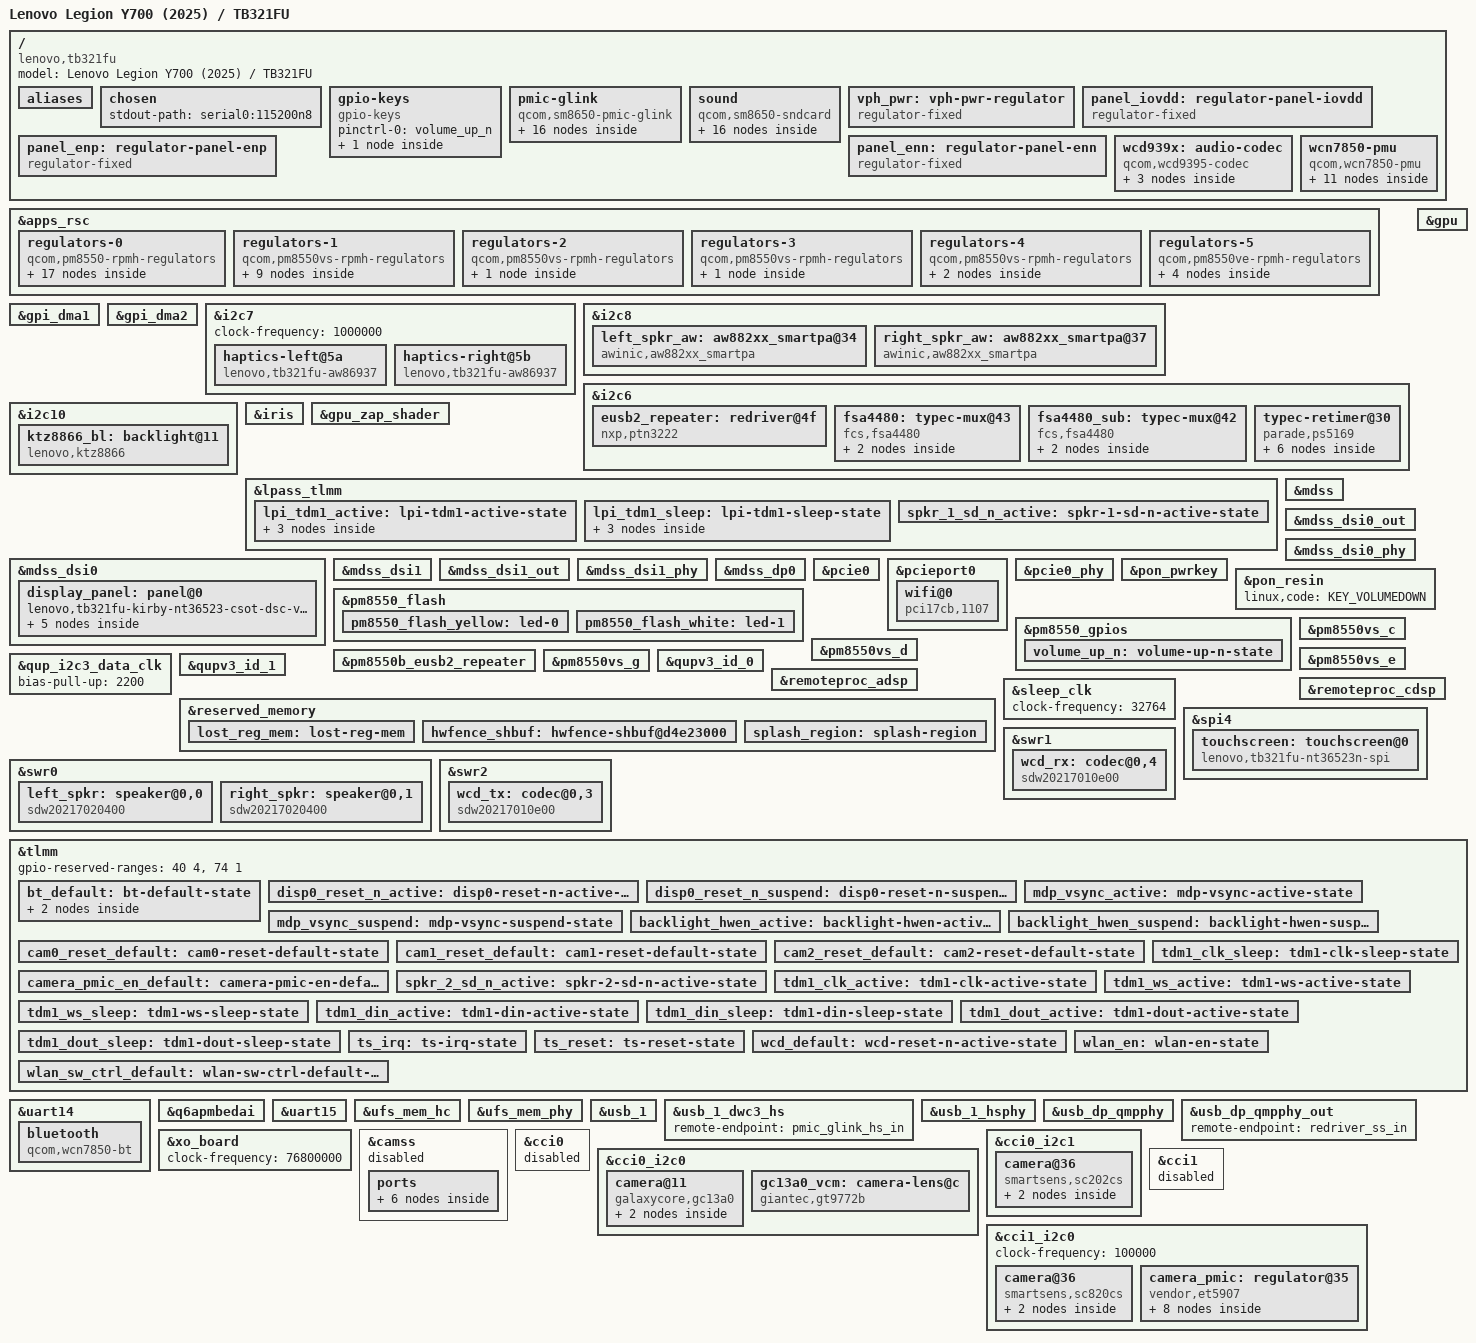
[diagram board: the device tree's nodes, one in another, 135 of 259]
// SPDX-License-Identifier: BSD-3-Clause
/*
 * Copyright (c) 2023, Linaro Limited
 */

/dts-v1/;

#include <dt-bindings/leds/common.h>
#include <dt-bindings/regulator/qcom,rpmh-regulator.h>
#include <dt-bindings/phy/phy.h>
#include "sm8650.dtsi"
#include "pm8550.dtsi"
#include "pm8550b.dtsi"
#define PMK8550VE_SID 8
#include "pm8550ve.dtsi"
#include "pm8550vs.dtsi"
#include "pmk8550.dtsi"

/delete-node/ &rmtfs_mem;
/delete-node/ &hwfence_shbuf;
/delete-node/ &remoteproc_mpss;
/delete-node/ &qlink_logging_mem;
/delete-node/ &mpss_dsm_mem;
/delete-node/ &mpss_dsm_mem_2;
/delete-node/ &mpss_mem;
/delete-node/ &q6_mpss_dtb_mem;

/ {
	model = "Lenovo Legion Y700 (2025) / TB321FU";
	compatible = "lenovo,tb321fu", "qcom,sm8650";

	aliases {
		serial0 = &uart15;
		serial1 = &uart14;
	};

	chosen {
		stdout-path = "serial0:115200n8";
	};

	gpio-keys {
		compatible = "gpio-keys";

		pinctrl-0 = <&volume_up_n>;
		pinctrl-names = "default";

		key-volume-up {
			label = "Volume Up";
			linux,code = <KEY_VOLUMEUP>;
			gpios = <&pm8550_gpios 6 GPIO_ACTIVE_LOW>;
			debounce-interval = <15>;
			linux,can-disable;
			wakeup-source;
		};
	};

		pmic-glink {
				compatible = "qcom,sm8650-pmic-glink",
					     "qcom,sm8550-pmic-glink",
					     "qcom,pmic-glink";
				#address-cells = <1>;
				#size-cells = <0>;
				c2-select-gpios = <&tlmm 58 GPIO_ACTIVE_HIGH>;
				secondary-audio-detect-gpios = <&tlmm 29 GPIO_ACTIVE_HIGH>;

				connector@0 {
					compatible = "usb-c-connector";
					reg = <0>;

			power-role = "dual";
			data-role = "dual";
			self-powered;

			ports {
				#address-cells = <1>;
				#size-cells = <0>;

				port@0 {
					reg = <0>;

					pmic_glink_hs_in: endpoint {
						remote-endpoint = <&usb_1_dwc3_hs>;
					};
				};

				port@1 {
					reg = <1>;

					pmic_glink_ss_in: endpoint {
						remote-endpoint = <&redriver_ss_out>;
					};
				};

				port@2 {
					reg = <2>;
					#address-cells = <1>;
					#size-cells = <0>;

					pmic_glink_sbu: endpoint@0 {
						reg = <0>;
						remote-endpoint = <&fsa4480_sbu_mux>;
					};

					pmic_glink_sbu_codec: endpoint@1 {
						reg = <1>;
						remote-endpoint = <&wcd_codec_headset_in>;
					};
					};
				};
			};

			connector@1 {
				compatible = "usb-c-connector";
				reg = <1>;

				power-role = "dual";
				data-role = "dual";
				self-powered;

				ports {
					#address-cells = <1>;
					#size-cells = <0>;

					port@1 {
						reg = <1>;

						pmic_glink_ss1_in: endpoint {
							remote-endpoint = <&redriver_ss1_out>;
						};
					};

					port@2 {
						reg = <2>;
						#address-cells = <1>;
						#size-cells = <0>;

						pmic_glink_sbu1: endpoint@0 {
							reg = <0>;
							remote-endpoint = <&fsa4480_sub_sbu_mux>;
						};

						pmic_glink_sbu1_codec: endpoint@1 {
							reg = <1>;
							remote-endpoint = <&wcd_codec_headset_in1>;
						};
					};
				};
			};
		};

	sound {
		compatible = "qcom,sm8650-sndcard", "qcom,sm8450-sndcard";
		model = "Lenovo-Y700-TB321FU";
		pinctrl-names = "default", "sleep";
			pinctrl-0 = <&tdm1_clk_active>, <&tdm1_ws_active>,
				    <&tdm1_din_active>, <&tdm1_dout_active>;
			pinctrl-1 = <&tdm1_clk_sleep>, <&tdm1_ws_sleep>,
				    <&tdm1_din_sleep>, <&tdm1_dout_sleep>;
		audio-routing = "IN1_HPHL", "HPHL_OUT",
				"IN2_HPHR", "HPHR_OUT",
				"AMIC1", "MIC BIAS1",
				"AMIC2", "MIC BIAS2",
				"AMIC3", "MIC BIAS3",
				"AMIC4", "MIC BIAS4",
				"AMIC5", "MIC BIAS4",
				"TX SWR_INPUT0", "ADC1_OUTPUT",
				"TX SWR_INPUT1", "ADC2_OUTPUT",
				"TX SWR_INPUT2", "ADC3_OUTPUT",
				"TX SWR_INPUT3", "ADC4_OUTPUT";

		wcd-playback-dai-link {
			link-name = "WCD Playback";

			cpu {
				sound-dai = <&q6apmbedai RX_CODEC_DMA_RX_0>;
			};

			codec {
				sound-dai = <&wcd939x 0>, <&swr1 0>, <&lpass_rxmacro 0>;
			};

			platform {
				sound-dai = <&q6apm>;
			};
		};

		wcd-capture-dai-link {
			link-name = "WCD Capture";

			cpu {
				sound-dai = <&q6apmbedai TX_CODEC_DMA_TX_3>;
			};

			codec {
				sound-dai = <&wcd939x 1>, <&swr2 1>, <&lpass_txmacro 0>;
			};

			platform {
				sound-dai = <&q6apm>;
			};
		};

		aw-spk-dai-link {
			link-name = "AW882xx Playback";

			cpu {
				sound-dai = <&q6apmbedai SECONDARY_TDM_RX_0>;
			};

			codec {
				sound-dai = <&left_spkr_aw>, <&right_spkr_aw>;
			};

			platform {
				sound-dai = <&q6apm>;
			};
		};

		/* Needs the DISPLAY_PORT_RX_0 path in the AudioReach topology. */
		dp-dai-link {
			link-name = "DisplayPort Playback";

			cpu {
				sound-dai = <&q6apmbedai DISPLAY_PORT_RX_0>;
			};

			codec {
				sound-dai = <&mdss_dp0>;
			};

			platform {
				sound-dai = <&q6apm>;
			};
		};
	};

	vph_pwr: vph-pwr-regulator {
		compatible = "regulator-fixed";

		regulator-name = "vph_pwr";
		regulator-min-microvolt = <3700000>;
		regulator-max-microvolt = <3700000>;

		regulator-always-on;
		regulator-boot-on;
	};


	panel_iovdd: regulator-panel-iovdd {
		compatible = "regulator-fixed";
		regulator-name = "panel_iovdd";
		regulator-min-microvolt = <1800000>;
		regulator-max-microvolt = <1800000>;
		gpio = <&pm8550ve_gpios 8 GPIO_ACTIVE_HIGH>;
		enable-active-high;
	};

	panel_enp: regulator-panel-enp {
		compatible = "regulator-fixed";
		regulator-name = "panel_enp";
		gpio = <&tlmm 72 GPIO_ACTIVE_HIGH>;
		enable-active-high;
	};

	panel_enn: regulator-panel-enn {
		compatible = "regulator-fixed";
		regulator-name = "panel_enn";
		gpio = <&tlmm 73 GPIO_ACTIVE_HIGH>;
		enable-active-high;
	};

	wcd939x: audio-codec {
		compatible = "qcom,wcd9395-codec", "qcom,wcd9390-codec";

		pinctrl-0 = <&wcd_default>;
		pinctrl-names = "default";

		qcom,micbias1-microvolt = <1800000>;
		qcom,micbias2-microvolt = <1800000>;
		qcom,micbias3-microvolt = <1800000>;
		qcom,micbias4-microvolt = <1800000>;
		qcom,mbhc-buttons-vthreshold-microvolt = <75000 150000 237000 500000 500000 500000 500000 500000>;
		qcom,mbhc-headset-vthreshold-microvolt = <1700000>;
		qcom,mbhc-headphone-vthreshold-microvolt = <50000>;
		qcom,rx-device = <&wcd_rx>;
		qcom,tx-device = <&wcd_tx>;

		reset-gpios = <&tlmm 107 GPIO_ACTIVE_LOW>;

	vdd-buck-supply = <&vreg_l15b_1p8>;
	vdd-rxtx-supply = <&vreg_l15b_1p8>;
	vdd-io-supply = <&vreg_l15b_1p8>;
	vdd-mic-bias-supply = <&vreg_bob1>;

		#sound-dai-cells = <1>;

		mode-switch;
		orientation-switch;

			port {
				#address-cells = <1>;
				#size-cells = <0>;

				wcd_codec_headset_in: endpoint@0 {
					reg = <0>;
					remote-endpoint = <&pmic_glink_sbu_codec>;
				};

				wcd_codec_headset_in1: endpoint@1 {
					reg = <1>;
					remote-endpoint = <&pmic_glink_sbu1_codec>;
				};
			};
	};

	wcn7850-pmu {
		compatible = "qcom,wcn7850-pmu";

		pinctrl-names = "default";
		pinctrl-0 = <&wlan_en>, <&bt_default>, <&wlan_sw_ctrl_default>;

		wlan-enable-gpios = <&tlmm 16 GPIO_ACTIVE_HIGH>;
		bt-enable-gpios = <&tlmm 17 GPIO_ACTIVE_HIGH>;

		vdd-supply = <&vreg_s4i_0p85>;
		vddio-supply = <&vreg_l15b_1p8>;
		vddio1p2-supply = <&vreg_l3c_1p2>;
		vddaon-supply = <&vreg_s2c_0p8>;
		vdddig-supply = <&vreg_s3c_0p9>;
		vddrfa1p2-supply = <&vreg_s1c_1p2>;
		vddrfa1p8-supply = <&vreg_s6c_1p8>;

		clocks = <&rpmhcc RPMH_RF_CLK1>;

		regulators {
			vreg_pmu_rfa_cmn: ldo0 {
				regulator-name = "vreg_pmu_rfa_cmn";
			};

			vreg_pmu_aon_0p59: ldo1 {
				regulator-name = "vreg_pmu_aon_0p59";
			};

			vreg_pmu_wlcx_0p8: ldo2 {
				regulator-name = "vreg_pmu_wlcx_0p8";
			};

			vreg_pmu_wlmx_0p85: ldo3 {
				regulator-name = "vreg_pmu_wlmx_0p85";
			};

			vreg_pmu_btcmx_0p85: ldo4 {
				regulator-name = "vreg_pmu_btcmx_0p85";
			};

			vreg_pmu_rfa_0p8: ldo5 {
				regulator-name = "vreg_pmu_rfa_0p8";
			};

			vreg_pmu_rfa_1p2: ldo6 {
				regulator-name = "vreg_pmu_rfa_1p2";
			};

			vreg_pmu_rfa_1p8: ldo7 {
				regulator-name = "vreg_pmu_rfa_1p8";
			};

			vreg_pmu_pcie_0p9: ldo8 {
				regulator-name = "vreg_pmu_pcie_0p9";
			};

			vreg_pmu_pcie_1p8: ldo9 {
				regulator-name = "vreg_pmu_pcie_1p8";
			};
		};
	};
};

&apps_rsc {
	regulators-0 {
		compatible = "qcom,pm8550-rpmh-regulators";

		vdd-bob1-supply = <&vph_pwr>;
		vdd-bob2-supply = <&vph_pwr>;
		vdd-l1-l4-l10-supply = <&vreg_s6c_1p8>;
		vdd-l2-l13-l14-supply = <&vreg_bob1>;
		vdd-l3-supply = <&vreg_s1c_1p2>;
		vdd-l5-l16-supply = <&vreg_bob1>;
		vdd-l6-l7-supply = <&vreg_bob1>;
		vdd-l8-l9-supply = <&vreg_bob1>;
		vdd-l11-supply = <&vreg_s1c_1p2>;
		vdd-l12-supply = <&vreg_s6c_1p8>;
		vdd-l15-supply = <&vreg_s6c_1p8>;
		vdd-l17-supply = <&vreg_bob2>;

		qcom,pmic-id = "b";

		vreg_bob1: bob1 {
			regulator-name = "vreg_bob1";
			regulator-min-microvolt = <3296000>;
			regulator-max-microvolt = <3960000>;
			regulator-initial-mode = <RPMH_REGULATOR_MODE_HPM>;
		};

		vreg_bob2: bob2 {
			regulator-name = "vreg_bob2";
			regulator-min-microvolt = <2720000>;
			regulator-max-microvolt = <3008000>;
			regulator-initial-mode = <RPMH_REGULATOR_MODE_HPM>;
		};

		vreg_l2b_3p0: ldo2 {
			regulator-name = "vreg_l2b_3p0";
			regulator-min-microvolt = <3008000>;
			regulator-max-microvolt = <3008000>;
			regulator-initial-mode = <RPMH_REGULATOR_MODE_HPM>;
			regulator-allow-set-load;
			regulator-allowed-modes = <RPMH_REGULATOR_MODE_LPM
						   RPMH_REGULATOR_MODE_HPM>;
		};

		vreg_l5b_3p1: ldo5 {
			regulator-name = "vreg_l5b_3p1";
			regulator-min-microvolt = <3104000>;
			regulator-max-microvolt = <3104000>;
			regulator-initial-mode = <RPMH_REGULATOR_MODE_HPM>;
			regulator-allow-set-load;
			regulator-allowed-modes = <RPMH_REGULATOR_MODE_LPM
						   RPMH_REGULATOR_MODE_HPM>;
		};

		vreg_l6b_1p8: ldo6 {
			regulator-name = "vreg_l6b_1p8";
			regulator-min-microvolt = <1800000>;
			regulator-max-microvolt = <3008000>;
			regulator-initial-mode = <RPMH_REGULATOR_MODE_HPM>;
			regulator-allow-set-load;
			regulator-allowed-modes = <RPMH_REGULATOR_MODE_LPM
						   RPMH_REGULATOR_MODE_HPM>;
		};

		vreg_l7b_1p8: ldo7 {
			regulator-name = "vreg_l7b_1p8";
			regulator-min-microvolt = <1800000>;
			regulator-max-microvolt = <3008000>;
			regulator-initial-mode = <RPMH_REGULATOR_MODE_HPM>;
		};

		vreg_l8b_1p8: ldo8 {
			regulator-name = "vreg_l8b_1p8";
			regulator-min-microvolt = <1800000>;
			regulator-max-microvolt = <3008000>;
			regulator-initial-mode = <RPMH_REGULATOR_MODE_HPM>;
			regulator-allow-set-load;
			regulator-allowed-modes = <RPMH_REGULATOR_MODE_LPM
						   RPMH_REGULATOR_MODE_HPM>;
		};

		vreg_l10b_1p8: ldo10 {
			regulator-name = "vreg_l10b_1p8";
			regulator-min-microvolt = <1800000>;
			regulator-max-microvolt = <1800000>;
			regulator-initial-mode = <RPMH_REGULATOR_MODE_HPM>;
			regulator-allow-set-load;
			regulator-boot-on;
			regulator-always-on;
			regulator-allowed-modes = <RPMH_REGULATOR_MODE_LPM
						   RPMH_REGULATOR_MODE_HPM>;
		};

		vreg_l11b_1p2: ldo11 {
			regulator-name = "vreg_l11b_1p2";
			regulator-min-microvolt = <1200000>;
			regulator-max-microvolt = <1504000>;
			regulator-initial-mode = <RPMH_REGULATOR_MODE_HPM>;
			regulator-allow-set-load;
			regulator-allowed-modes = <RPMH_REGULATOR_MODE_LPM
						   RPMH_REGULATOR_MODE_HPM>;
		};

		vreg_l12b_1p8: ldo12 {
			regulator-name = "vreg_l12b_1p8";
			regulator-min-microvolt = <1800000>;
			regulator-max-microvolt = <1800000>;
			regulator-initial-mode = <RPMH_REGULATOR_MODE_HPM>;
			regulator-allow-set-load;
			regulator-allowed-modes = <RPMH_REGULATOR_MODE_LPM
						   RPMH_REGULATOR_MODE_HPM>;
		};

		vreg_l13b_3p0: ldo13 {
			regulator-name = "vreg_l13b_3p0";
			regulator-min-microvolt = <3000000>;
			regulator-max-microvolt = <3000000>;
			regulator-initial-mode = <RPMH_REGULATOR_MODE_HPM>;
			regulator-allow-set-load;
			regulator-allowed-modes = <RPMH_REGULATOR_MODE_LPM
						   RPMH_REGULATOR_MODE_HPM>;
		};

		vreg_l14b_3p2: ldo14 {
			regulator-name = "vreg_l14b_3p2";
			regulator-min-microvolt = <3200000>;
			regulator-max-microvolt = <3200000>;
			regulator-initial-mode = <RPMH_REGULATOR_MODE_HPM>;
			regulator-allow-set-load;
			regulator-allowed-modes = <RPMH_REGULATOR_MODE_LPM
						   RPMH_REGULATOR_MODE_HPM>;
		};

		vreg_l15b_1p8: ldo15 {
			regulator-name = "vreg_l15b_1p8";
			regulator-min-microvolt = <1800000>;
			regulator-max-microvolt = <1800000>;
			regulator-initial-mode = <RPMH_REGULATOR_MODE_HPM>;
			regulator-allow-set-load;
			regulator-allowed-modes = <RPMH_REGULATOR_MODE_LPM
						   RPMH_REGULATOR_MODE_HPM>;
		};

		vreg_l16b_2p8: ldo16 {
			regulator-name = "vreg_l16b_2p8";
			regulator-min-microvolt = <2800000>;
			regulator-max-microvolt = <2800000>;
			regulator-initial-mode = <RPMH_REGULATOR_MODE_HPM>;
			regulator-allow-set-load;
			regulator-allowed-modes = <RPMH_REGULATOR_MODE_LPM
						   RPMH_REGULATOR_MODE_HPM>;
		};

		vreg_l17b_2p5: ldo17 {
			regulator-name = "vreg_l17b_2p5";
			regulator-min-microvolt = <2504000>;
			regulator-max-microvolt = <2504000>;
			regulator-initial-mode = <RPMH_REGULATOR_MODE_HPM>;
			regulator-allow-set-load;
			regulator-allowed-modes = <RPMH_REGULATOR_MODE_LPM
						   RPMH_REGULATOR_MODE_HPM>;
		};
	};

	regulators-1 {
		compatible = "qcom,pm8550vs-rpmh-regulators";

		vdd-l1-supply = <&vreg_s1c_1p2>;
		vdd-l2-supply = <&vreg_s1c_1p2>;
		vdd-l3-supply = <&vreg_s1c_1p2>;
		vdd-s1-supply = <&vph_pwr>;
		vdd-s2-supply = <&vph_pwr>;
		vdd-s3-supply = <&vph_pwr>;
		vdd-s4-supply = <&vph_pwr>;
		vdd-s5-supply = <&vph_pwr>;
		vdd-s6-supply = <&vph_pwr>;

		qcom,pmic-id = "c";

		vreg_s1c_1p2: smps1 {
			regulator-name = "vreg_s1c_1p2";
			regulator-min-microvolt = <1256000>;
			regulator-max-microvolt = <1348000>;
			regulator-initial-mode = <RPMH_REGULATOR_MODE_HPM>;
		};

		vreg_s2c_0p8: smps2 {
			regulator-name = "vreg_s2c_0p8";
			regulator-min-microvolt = <852000>;
			regulator-max-microvolt = <1036000>;
			regulator-initial-mode = <RPMH_REGULATOR_MODE_HPM>;
		};

		vreg_s3c_0p9: smps3 {
			regulator-name = "vreg_s3c_0p9";
			regulator-min-microvolt = <976000>;
			regulator-max-microvolt = <1064000>;
			regulator-initial-mode = <RPMH_REGULATOR_MODE_HPM>;
		};

		vreg_s4c_1p2: smps4 {
			regulator-name = "vreg_s4c_1p2";
			regulator-min-microvolt = <1224000>;
			regulator-max-microvolt = <1280000>;
			regulator-initial-mode = <RPMH_REGULATOR_MODE_HPM>;
		};

		vreg_s5c_0p7: smps5 {
			regulator-name = "vreg_s5c_0p7";
			regulator-min-microvolt = <752000>;
			regulator-max-microvolt = <900000>;
			regulator-initial-mode = <RPMH_REGULATOR_MODE_HPM>;
		};

		vreg_s6c_1p8: smps6 {
			regulator-name = "vreg_s6c_1p8";
			regulator-min-microvolt = <1856000>;
			regulator-max-microvolt = <2000000>;
			regulator-initial-mode = <RPMH_REGULATOR_MODE_HPM>;
		};

		vreg_l1c_1p2: ldo1 {
			regulator-name = "vreg_l1c_1p2";
			regulator-min-microvolt = <1200000>;
			regulator-max-microvolt = <1200000>;
			regulator-initial-mode = <RPMH_REGULATOR_MODE_HPM>;
			regulator-allow-set-load;
			regulator-allowed-modes = <RPMH_REGULATOR_MODE_LPM
						   RPMH_REGULATOR_MODE_HPM>;
		};

		vreg_l3c_1p2: ldo3 {
			regulator-name = "vreg_l3c_1p2";
			regulator-min-microvolt = <1200000>;
			regulator-max-microvolt = <1200000>;
			regulator-initial-mode = <RPMH_REGULATOR_MODE_HPM>;
			regulator-allow-set-load;
			regulator-allowed-modes = <RPMH_REGULATOR_MODE_LPM
						   RPMH_REGULATOR_MODE_HPM>;
		};
	};

	regulators-2 {
		compatible = "qcom,pm8550vs-rpmh-regulators";

		vdd-l1-supply = <&vreg_s3c_0p9>;

		qcom,pmic-id = "d";

		vreg_l1d_0p88: ldo1 {
			regulator-name = "vreg_l1d_0p88";
			regulator-min-microvolt = <912000>;
			regulator-max-microvolt = <920000>;
			regulator-initial-mode = <RPMH_REGULATOR_MODE_HPM>;
			regulator-allow-set-load;
			regulator-allowed-modes = <RPMH_REGULATOR_MODE_LPM
						   RPMH_REGULATOR_MODE_HPM>;
		};
	};

	regulators-3 {
		compatible = "qcom,pm8550vs-rpmh-regulators";

		vdd-l3-supply = <&vreg_s3c_0p9>;

		qcom,pmic-id = "e";

		vreg_l3e_0p9: ldo3 {
			regulator-name = "vreg_l3e_0p9";
			regulator-min-microvolt = <880000>;
			regulator-max-microvolt = <920000>;
			regulator-initial-mode = <RPMH_REGULATOR_MODE_HPM>;
			regulator-allow-set-load;
			regulator-allowed-modes = <RPMH_REGULATOR_MODE_LPM
						   RPMH_REGULATOR_MODE_HPM>;
		};
	};

	regulators-4 {
		compatible = "qcom,pm8550vs-rpmh-regulators";

		vdd-l1-supply = <&vreg_s3c_0p9>;
		vdd-l3-supply = <&vreg_s3c_0p9>;

		qcom,pmic-id = "g";

		vreg_l1g_0p91: ldo1 {
			regulator-name = "vreg_l1g_0p91";
			regulator-min-microvolt = <912000>;
			regulator-max-microvolt = <920000>;
			regulator-initial-mode = <RPMH_REGULATOR_MODE_HPM>;
			regulator-allow-set-load;
			regulator-allowed-modes = <RPMH_REGULATOR_MODE_LPM
						   RPMH_REGULATOR_MODE_HPM>;
		};

		vreg_l3g_0p91: ldo3 {
			regulator-name = "vreg_l3g_0p91";
			regulator-min-microvolt = <880000>;
			regulator-max-microvolt = <912000>;
			regulator-initial-mode = <RPMH_REGULATOR_MODE_HPM>;
			regulator-allow-set-load;
			regulator-allowed-modes = <RPMH_REGULATOR_MODE_LPM
						   RPMH_REGULATOR_MODE_HPM>;
		};
	};

	regulators-5 {
		compatible = "qcom,pm8550ve-rpmh-regulators";

		vdd-l1-supply = <&vreg_s3c_0p9>;
		vdd-l2-supply = <&vreg_s3c_0p9>;
		vdd-l3-supply = <&vreg_s1c_1p2>;
		vdd-s4-supply = <&vph_pwr>;

		qcom,pmic-id = "i";

		vreg_s4i_0p85: smps4 {
			regulator-name = "vreg_s4i_0p85";
			regulator-min-microvolt = <852000>;
			regulator-max-microvolt = <1004000>;
			regulator-initial-mode = <RPMH_REGULATOR_MODE_HPM>;
		};

		vreg_l1i_0p88: ldo1 {
			regulator-name = "vreg_l1i_0p88";
			regulator-min-microvolt = <880000>;
			regulator-max-microvolt = <912000>;
			regulator-initial-mode = <RPMH_REGULATOR_MODE_HPM>;
			regulator-allow-set-load;
			regulator-allowed-modes = <RPMH_REGULATOR_MODE_LPM
						   RPMH_REGULATOR_MODE_HPM>;
		};

		vreg_l2i_0p88: ldo2 {
			regulator-name = "vreg_l2i_0p88";
			regulator-min-microvolt = <880000>;
			regulator-max-microvolt = <912000>;
			regulator-initial-mode = <RPMH_REGULATOR_MODE_HPM>;
			regulator-allow-set-load;
			regulator-allowed-modes = <RPMH_REGULATOR_MODE_LPM
						   RPMH_REGULATOR_MODE_HPM>;
		};

		vreg_l3i_1p2: ldo3 {
			regulator-name = "vreg_l3i_0p91";
			regulator-min-microvolt = <1200000>;
			regulator-max-microvolt = <1200000>;
			regulator-initial-mode = <RPMH_REGULATOR_MODE_HPM>;
			regulator-allow-set-load;
			regulator-allowed-modes = <RPMH_REGULATOR_MODE_LPM
						   RPMH_REGULATOR_MODE_HPM>;
		};
	};
};

&gpi_dma1 {
	status = "okay";
};

&gpi_dma2 {
	status = "okay";
};

&i2c7 {
	status = "okay";
	clock-frequency = <1000000>;

	haptics-left@5a {
		compatible = "lenovo,tb321fu-aw86937", "awinic,aw86937";
		reg = <0x5a>;
		label = "aw86937-haptics-left";
	};

	haptics-right@5b {
		compatible = "lenovo,tb321fu-aw86937", "awinic,aw86937";
		reg = <0x5b>;
		label = "aw86937-haptics-right";
	};
};

&i2c8 {
	status = "okay";

	left_spkr_aw: aw882xx_smartpa@34 {
		compatible = "awinic,aw882xx_smartpa";
		/* Speaker volume linear in dB over 28.4 dB (kernel patch 0023) */
		awinic,linear-volume-range-cdb = <2840>;
		reg = <0x34>;
		#sound-dai-cells = <0>;
		aw-cali-mode = "none";
		aw-re-max = <0x7530>;
		aw-re-min = <0x0fa0>;
		rename-flag = <1>;
		sound-channel = <0>;
		sync-load = <1>;
		one_rst_flag = <1>;
		reset-gpio = <&tlmm 120 GPIO_ACTIVE_HIGH>;
	};

	right_spkr_aw: aw882xx_smartpa@37 {
		compatible = "awinic,aw882xx_smartpa";
		/* Speaker volume linear in dB over 28.4 dB (kernel patch 0023) */
		awinic,linear-volume-range-cdb = <2840>;
		reg = <0x37>;
		#sound-dai-cells = <0>;
		aw-cali-mode = "none";
		aw-re-max = <0x7530>;
		aw-re-min = <0x0fa0>;
		rename-flag = <1>;
		sound-channel = <1>;
		sync-load = <1>;
		one_rst_flag = <2>;
		reset-gpio = <&tlmm 128 GPIO_ACTIVE_HIGH>;
	};
};

&i2c6 {
	status = "okay";

	eusb2_repeater: redriver@4f {
		compatible = "nxp,ptn3222";
		reg = <0x4f>;

		vdd1v8-supply = <&vreg_l15b_1p8>;
		vdd3v3-supply = <&vreg_l5b_3p1>;

		reset-gpios = <&pm8550vs_c_gpios 4 GPIO_ACTIVE_LOW>;
		qcom,param-override-seq-c1 = /bits/ 8 <0x40 0x06 0x22 0x07 0x65 0x08 0x03 0x0a>;

		#phy-cells = <0>;
	};

		fsa4480: typec-mux@43 {
			compatible = "fcs,fsa4480";
			reg = <0x43>;

		vcc-supply = <&vreg_l15b_1p8>;

		mode-switch;
		orientation-switch;

		port {
			fsa4480_sbu_mux: endpoint {
				remote-endpoint = <&pmic_glink_sbu>;
				};
			};
		};

		fsa4480_sub: typec-mux@42 {
			compatible = "fcs,fsa4480";
			reg = <0x42>;

			vcc-supply = <&vreg_l15b_1p8>;

			mode-switch;
			orientation-switch;

			port {
				fsa4480_sub_sbu_mux: endpoint {
					remote-endpoint = <&pmic_glink_sbu1>;
				};
			};
		};

		typec-retimer@30 {
			compatible = "parade,ps5169", "hq_redriver,ps5169";
		reg = <0x30>;

		retimer-switch;
		orientation-switch;

		ports {
			#address-cells = <1>;
			#size-cells = <0>;

				port@0 {
					reg = <0>;
					#address-cells = <1>;
					#size-cells = <0>;

					redriver_ss_out: endpoint@0 {
						reg = <0>;
						remote-endpoint = <&pmic_glink_ss_in>;
					};

					redriver_ss1_out: endpoint@1 {
						reg = <1>;
						remote-endpoint = <&pmic_glink_ss1_in>;
					};
				};

			port@1 {
				reg = <1>;

				redriver_ss_in: endpoint {
					data-lanes = <3 2 1 0>;
					remote-endpoint = <&usb_dp_qmpphy_out>;
				};
			};
		};
	};
};

&i2c10 {
	status = "okay";

		ktz8866_bl: backlight@11 {
			compatible = "lenovo,ktz8866", "kinetic,ktz8866";
			reg = <0x11>;

		pinctrl-0 = <&backlight_hwen_active>;
		pinctrl-1 = <&backlight_hwen_suspend>;
		pinctrl-names = "default", "sleep";
		enable-gpios = <&tlmm 87 GPIO_ACTIVE_HIGH>;

		current-num-sinks = <4>;
		max-brightness = <2047>;
			default-brightness-level = <1027>;
		};

	};

&iris {
	status = "okay";
};

&gpu {
	status = "okay";
};

&gpu_zap_shader {
	firmware-name = "qcom/sm8650/lenovo/tb321fu/gen70900_zap.mbn";
};

&lpass_tlmm {
	lpi_tdm1_active: lpi-tdm1-active-state {
		clk-pins {
			pins = "gpio6";
			function = "i2s1_clk";
			drive-strength = <8>;
			bias-disable;
			output-high;
		};

		ws-pins {
			pins = "gpio7";
			function = "i2s1_ws";
			drive-strength = <8>;
			bias-disable;
			output-high;
		};

		data-pins {
			pins = "gpio8", "gpio9";
			function = "i2s1_data";
			drive-strength = <8>;
			bias-disable;
			output-high;
		};
	};

	lpi_tdm1_sleep: lpi-tdm1-sleep-state {
		clk-pins {
			pins = "gpio6";
			function = "i2s1_clk";
			drive-strength = <2>;
			bias-pull-down;
			input-enable;
		};

		ws-pins {
			pins = "gpio7";
			function = "i2s1_ws";
			drive-strength = <2>;
			bias-pull-down;
			input-enable;
		};

		data-pins {
			pins = "gpio8", "gpio9";
			function = "i2s1_data";
			drive-strength = <2>;
			bias-pull-down;
			input-enable;
		};
	};

	spkr_1_sd_n_active: spkr-1-sd-n-active-state {
		pins = "gpio21";
		function = "gpio";
		drive-strength = <16>;
		bias-disable;
		output-low;
	};
};

&mdss {
	status = "okay";
};

&mdss_dsi0 {
	vdda-supply = <&vreg_l3i_1p2>;
	qcom,dual-dsi-mode;
	qcom,sync-dual-dsi;
	qcom,master-dsi;
	status = "okay";

	display_panel: panel@0 {
		compatible = "lenovo,tb321fu-kirby-nt36523-csot-dsc-vid",
			     "lenovo,kirby-nt36523-csot-dsc-vid",
			     "lenovo,tb321fu-kirby-nt36523-csot-dsc",
			     "lenovo,kirby-nt36523-csot-dsc";
		reg = <0>;
		panel-name = "kirby_nt36523_csot_dsc_vid";
		vddio-supply = <&panel_iovdd>;
		enp-supply = <&panel_enp>;
		enn-supply = <&panel_enn>;
		reset-gpios = <&tlmm 133 GPIO_ACTIVE_LOW>;
		pinctrl-names = "default", "sleep";
		pinctrl-0 = <&disp0_reset_n_active>, <&mdp_vsync_active>;
		pinctrl-1 = <&disp0_reset_n_suspend>, <&mdp_vsync_suspend>;
		backlight = <&ktz8866_bl>;
		rotation = <90>;

		ports {
			#address-cells = <1>;
			#size-cells = <0>;

			port@0 {
				reg = <0>;

				panel_in_0: endpoint {
					remote-endpoint = <&mdss_dsi0_out>;
				};
			};

			port@1 {
				reg = <1>;

				panel_in_1: endpoint {
					remote-endpoint = <&mdss_dsi1_out>;
				};
			};
		};
	};
};

&mdss_dsi0_out {
	data-lanes = <0 1 2>;
	remote-endpoint = <&panel_in_0>;
};

&mdss_dsi0_phy {
	vdds-supply = <&vreg_l1i_0p88>;
	phy-type = <PHY_TYPE_CPHY>;
	qcom,mdss-dsi-panel-phy-timings = [00 00 00 00 23 22 08 19 08 02 04 00 00 00];

	status = "okay";
};

&mdss_dsi1 {
	vdda-supply = <&vreg_l3i_1p2>;
	qcom,dual-dsi-mode;
	qcom,sync-dual-dsi;
	/* DSI1 is slave, so use DSI0 clocks */
	assigned-clock-parents = <&mdss_dsi0_phy DSI_BYTE_PLL_CLK>,
				 <&mdss_dsi0_phy DSI_PIXEL_PLL_CLK>;

	status = "okay";
};

&mdss_dsi1_out {
	data-lanes = <0 1 2>;
	remote-endpoint = <&panel_in_1>;
};

&mdss_dsi1_phy {
	vdds-supply = <&vreg_l1i_0p88>;
	phy-type = <PHY_TYPE_CPHY>;
	qcom,mdss-dsi-panel-phy-timings = [00 00 00 00 23 22 08 19 08 02 04 00 00 00];

	status = "okay";
};

&mdss_dp0 {
	status = "okay";
};

&pcie0 {
	wake-gpios = <&tlmm 96 GPIO_ACTIVE_HIGH>;
	perst-gpios = <&tlmm 94 GPIO_ACTIVE_LOW>;

	pinctrl-0 = <&pcie0_default_state>;
	pinctrl-names = "default";

	status = "okay";
};

&pcieport0 {
	wifi@0 {
		compatible = "pci17cb,1107";
		reg = <0x10000 0x0 0x0 0x0 0x0>;

		vddrfacmn-supply = <&vreg_pmu_rfa_cmn>;
		vddaon-supply = <&vreg_pmu_aon_0p59>;
		vddwlcx-supply = <&vreg_pmu_wlcx_0p8>;
		vddwlmx-supply = <&vreg_pmu_wlmx_0p85>;
		vddrfa0p8-supply = <&vreg_pmu_rfa_0p8>;
		vddrfa1p2-supply = <&vreg_pmu_rfa_1p2>;
		vddrfa1p8-supply = <&vreg_pmu_rfa_1p8>;
		vddpcie0p9-supply = <&vreg_pmu_pcie_0p9>;
		vddpcie1p8-supply = <&vreg_pmu_pcie_1p8>;
	};
};

&pcie0_phy {
	vdda-phy-supply = <&vreg_l1i_0p88>;
	vdda-pll-supply = <&vreg_l3i_1p2>;

	status = "okay";
};

&pon_pwrkey {
	status = "okay";
};

&pon_resin {
	linux,code = <KEY_VOLUMEDOWN>;

	status = "okay";
};

&pm8550_flash {
	status = "okay";

	pm8550_flash_yellow: led-0 {
		function = LED_FUNCTION_FLASH;
		color = <LED_COLOR_ID_YELLOW>;
		led-sources = <1>, <4>;
		led-max-microamp = <500000>;
		flash-max-microamp = <2000000>;
		flash-max-timeout-us = <1280000>;
		function-enumerator = <0>;
	};

	pm8550_flash_white: led-1 {
		function = LED_FUNCTION_FLASH;
		color = <LED_COLOR_ID_WHITE>;
		led-sources = <2>, <3>;
		led-max-microamp = <500000>;
		flash-max-microamp = <2000000>;
		flash-max-timeout-us = <1280000>;
		function-enumerator = <1>;
	};
};

&pm8550_gpios {
	volume_up_n: volume-up-n-state {
		pins = "gpio6";
		function = "normal";
		bias-pull-up;
		input-enable;
		power-source = <1>;
	};
};

&pm8550b_eusb2_repeater {
	vdd18-supply = <&vreg_l15b_1p8>;
	vdd3-supply = <&vreg_l5b_3p1>;
	qcom,tune-usb2-amplitude = /bits/ 8 <0x0d>;
	qcom,tune-usb2-disc-thres = /bits/ 8 <0x06>;
	qcom,tune-usb2-preem = /bits/ 8 <0x07>;
	qcom,squelch-detector = <(-4000)>;
};

&pm8550vs_c {
	status = "okay";
};

&pm8550vs_d {
	status = "okay";
};

&pm8550vs_e {
	status = "okay";
};

&pm8550vs_g {
	status = "okay";
};

&qup_i2c3_data_clk {
	/* Use internal I2C pull-up */
	bias-pull-up = <2200>;
};

&qupv3_id_0 {
	status = "okay";
};

&qupv3_id_1 {
	status = "okay";
};

&remoteproc_adsp {
	firmware-name = "qcom/sm8650/lenovo/tb321fu/adsp.mdt",
			"qcom/sm8650/lenovo/tb321fu/adsp_dtb.mdt";

	status = "okay";
};

&remoteproc_cdsp {
	firmware-name = "qcom/sm8650/lenovo/tb321fu/cdsp.mdt",
			"qcom/sm8650/lenovo/tb321fu/cdsp_dtb.mdt";

	status = "okay";
};

&reserved_memory {
	lost_reg_mem: lost-reg-mem {
		reg = <0 0x9b09c000 0 0x4000>;
		no-map;
	};

	hwfence_shbuf: hwfence-shbuf@d4e23000 {
		reg = <0 0xd4e23000 0 0x2dd000>;
		no-map;
	};

	splash_region: splash-region {
		label = "cont_splash_region";
		reg = <0 0xd5100000 0 0x2b00000>;
		no-map;
	};
};

&sleep_clk {
	clock-frequency = <32764>;
};

&spi4 {
	status = "okay";

	touchscreen: touchscreen@0 {
		compatible = "lenovo,tb321fu-nt36523n-spi",
			     "novatek,nt36523n-spi",
			     "novatek,NVT-ts-spi";
		reg = <0>;

		reset-gpios = <&tlmm 161 GPIO_ACTIVE_HIGH>;
		irq-gpio = <&tlmm 162 GPIO_ACTIVE_LOW>;
		novatek,reset-gpio = <&tlmm 161 GPIO_ACTIVE_HIGH>;
		novatek,irq-gpio = <&tlmm 162 GPIO_ACTIVE_LOW>;

		vdd-supply = <&vreg_l14b_3p2>;
		vio-supply = <&vreg_l12b_1p8>;

		spi-max-frequency = <9600000>;
		novatek,swrst-n8-addr = <0x03f0fe>;
		novatek,spi-rd-fast-addr = <0x03f310>;
		novatek,pen-support;

		touchscreen-size-x = <1600>;
		touchscreen-size-y = <2560>;

		firmware-name = "qcom/sm8650/lenovo/tb321fu/novatek_ts_csot_fw.bin";
		panel = <&display_panel>;

		pinctrl-names = "default";
		pinctrl-0 = <&ts_reset>, <&ts_irq>;
	};
};

&swr0 {
	status = "okay";

	/* WSA8845, Speaker Left */
	left_spkr: speaker@0,0 {
		compatible = "sdw20217020400";
		reg = <0 0>;
		pinctrl-0 = <&spkr_1_sd_n_active>;
		pinctrl-names = "default";
		powerdown-gpios = <&lpass_tlmm 21 GPIO_ACTIVE_LOW>;
		#sound-dai-cells = <0>;
		sound-name-prefix = "SpkrLeft";
		vdd-1p8-supply = <&vreg_l15b_1p8>;
		vdd-io-supply = <&vreg_l3c_1p2>;

		/*
		 * WSA8845 Port 1 (DAC)     <=> SWR0 Port 1 (SPKR_L)
		 * WSA8845 Port 2 (COMP)    <=> SWR0 Port 2 (SPKR_L_COMP)
		 * WSA8845 Port 3 (BOOST)   <=> SWR0 Port 3 (SPKR_L_BOOST)
		 * WSA8845 Port 4 (PBR)     <=> SWR0 Port 7 (PBR)
		 * WSA8845 Port 5 (VISENSE) <=> SWR0 Port 10 (SPKR_L_VI)
		 * WSA8845 Port 6 (CPS)     <=> SWR0 Port 13 (CPS)
		 */
		qcom,port-mapping = <1 2 3 7 10 13>;
	};

	/* WSA8845, Speaker Right */
	right_spkr: speaker@0,1 {
		compatible = "sdw20217020400";
		reg = <0 1>;
		pinctrl-0 = <&spkr_2_sd_n_active>;
		pinctrl-names = "default";
		powerdown-gpios = <&tlmm 77 GPIO_ACTIVE_LOW>;
		#sound-dai-cells = <0>;
		sound-name-prefix = "SpkrRight";
		vdd-1p8-supply = <&vreg_l15b_1p8>;
		vdd-io-supply = <&vreg_l3c_1p2>;

		/*
		 * WSA8845 Port 1 (DAC)     <=> SWR0 Port 4 (SPKR_R)
		 * WSA8845 Port 2 (COMP)    <=> SWR0 Port 5 (SPKR_R_COMP)
		 * WSA8845 Port 3 (BOOST)   <=> SWR0 Port 6 (SPKR_R_BOOST)
		 * WSA8845 Port 4 (PBR)     <=> SWR0 Port 7 (PBR)
		 * WSA8845 Port 5 (VISENSE) <=> SWR0 Port 11 (SPKR_R_VI)
		 * WSA8845 Port 6 (CPS)     <=> SWR0 Port 13 (CPS)
		 */
		qcom,port-mapping = <4 5 6 7 11 13>;
	};
};

&swr1 {
	status = "okay";

	/* WCD9395 RX */
	wcd_rx: codec@0,4 {
		compatible = "sdw20217010e00";
		reg = <0 4>;

		/*
		 * WCD9395 RX Port 1 (HPH_L/R)      <=> SWR1 Port 1 (HPH_L/R)
		 * WCD9395 RX Port 2 (CLSH)         <=> SWR1 Port 2 (CLSH)
		 * WCD9395 RX Port 3 (COMP_L/R)     <=> SWR1 Port 3 (COMP_L/R)
		 * WCD9395 RX Port 4 (LO)           <=> SWR1 Port 4 (LO)
		 * WCD9395 RX Port 5 (DSD_L/R)      <=> SWR1 Port 5 (DSD_L/R)
		 * WCD9395 RX Port 6 (HIFI_PCM_L/R) <=> SWR1 Port 9 (HIFI_PCM_L/R)
		 */
		qcom,rx-port-mapping = <1 2 3 4 5 9>;
	};
};

&swr2 {
	status = "okay";

	/* WCD9395 TX */
	wcd_tx: codec@0,3 {
		compatible = "sdw20217010e00";
		reg = <0 3>;

		/*
		 * WCD9395 TX Port 1 (ADC1,2,3,4)         <=> SWR2 Port 2 (TX SWR_INPUT 0,1,2,3)
		 * WCD9395 TX Port 2 (ADC3,4 & DMIC0,1)   <=> SWR2 Port 2 (TX SWR_INPUT 0,1,2,3)
		 * WCD9395 TX Port 3 (DMIC0,1,2,3 & MBHC) <=> SWR2 Port 3 (TX SWR_INPUT 4,5,6,7)
		 * WCD9395 TX Port 4 (DMIC4,5,6,7)        <=> SWR2 Port 4 (TX SWR_INPUT 8,9,10,11)
		 */
		qcom,tx-port-mapping = <2 2 3 4>;
	};
};

&tlmm {
	/* Reserved I/Os for NFC */
	gpio-reserved-ranges = <40 4>, <74 1>;

	bt_default: bt-default-state {
		bt-en-pins {
			pins = "gpio17";
			function = "gpio";
			drive-strength = <16>;
			bias-disable;
		};

		sw-ctrl-pins {
			pins = "gpio18";
			function = "gpio";
			bias-pull-down;
		};
	};

	disp0_reset_n_active: disp0-reset-n-active-state {
		pins = "gpio133";
		function = "gpio";
		drive-strength = <8>;
		bias-disable;
	};

	disp0_reset_n_suspend: disp0-reset-n-suspend-state {
		pins = "gpio133";
		function = "gpio";
		drive-strength = <2>;
		bias-pull-down;
	};

	mdp_vsync_active: mdp-vsync-active-state {
		pins = "gpio86";
		function = "mdp_vsync";
		drive-strength = <2>;
		bias-pull-down;
	};

	mdp_vsync_suspend: mdp-vsync-suspend-state {
		pins = "gpio86";
		function = "gpio";
		drive-strength = <2>;
		bias-pull-down;
	};

	backlight_hwen_active: backlight-hwen-active-state {
		pins = "gpio87";
		function = "gpio";
		drive-strength = <8>;
		bias-disable;
		output-high;
	};

	backlight_hwen_suspend: backlight-hwen-suspend-state {
		pins = "gpio87";
		function = "gpio";
		drive-strength = <2>;
		bias-pull-down;
		output-low;
	};

	cam0_reset_default: cam0-reset-default-state {
		pins = "gpio11";
		function = "gpio";
		drive-strength = <2>;
		bias-disable;
	};

	cam1_reset_default: cam1-reset-default-state {
		pins = "gpio109";
		function = "gpio";
		drive-strength = <2>;
		bias-disable;
	};

	cam2_reset_default: cam2-reset-default-state {
		pins = "gpio15";
		function = "gpio";
		drive-strength = <2>;
		bias-disable;
	};

	camera_pmic_en_default: camera-pmic-en-default-state {
		pins = "gpio126";
		function = "gpio";
		drive-strength = <2>;
		bias-disable;
		output-high;
	};

	spkr_2_sd_n_active: spkr-2-sd-n-active-state {
		pins = "gpio77";
		function = "gpio";
		drive-strength = <16>;
		bias-disable;
		output-low;
	};

	tdm1_clk_active: tdm1-clk-active-state {
		pins = "gpio121";
		function = "i2s1_sck";
		drive-strength = <8>;
		bias-disable;
		output-high;
	};

	tdm1_clk_sleep: tdm1-clk-sleep-state {
		pins = "gpio121";
		function = "gpio";
		drive-strength = <2>;
		bias-pull-down;
		input-enable;
	};

	tdm1_ws_active: tdm1-ws-active-state {
		pins = "gpio123";
		function = "i2s1_ws";
		drive-strength = <8>;
		bias-disable;
		output-high;
	};

	tdm1_ws_sleep: tdm1-ws-sleep-state {
		pins = "gpio123";
		function = "gpio";
		drive-strength = <2>;
		bias-pull-down;
		input-enable;
	};

	tdm1_din_active: tdm1-din-active-state {
		pins = "gpio122";
		function = "i2s1_data0";
		drive-strength = <8>;
		bias-disable;
	};

	tdm1_din_sleep: tdm1-din-sleep-state {
		pins = "gpio122";
		function = "gpio";
		drive-strength = <2>;
		bias-pull-down;
		input-enable;
	};

	tdm1_dout_active: tdm1-dout-active-state {
		pins = "gpio124";
		function = "i2s1_data1";
		drive-strength = <8>;
		bias-disable;
	};

	tdm1_dout_sleep: tdm1-dout-sleep-state {
		pins = "gpio124";
		function = "gpio";
		drive-strength = <2>;
		bias-pull-down;
		input-enable;
	};

	ts_irq: ts-irq-state {
		pins = "gpio162";
		function = "gpio";
		drive-strength = <8>;
		bias-pull-up;
		output-disable;
	};

	ts_reset: ts-reset-state {
		pins = "gpio161";
		function = "gpio";
		drive-strength = <8>;
		bias-pull-up;
	};

	wcd_default: wcd-reset-n-active-state {
		pins = "gpio107";
		function = "gpio";
		drive-strength = <16>;
		bias-disable;
		output-low;
	};

	wlan_en: wlan-en-state {
		pins = "gpio16";
		function = "gpio";
		drive-strength = <8>;
		bias-pull-down;
	};

	wlan_sw_ctrl_default: wlan-sw-ctrl-default-state {
		pins = "gpio18", "gpio19";
		function = "gpio";
		drive-strength = <2>;
		bias-disable;
		output-high;
	};
};

&uart14 {
	status = "okay";

	bluetooth {
		compatible = "qcom,wcn7850-bt";
		firmware-name = "hmtnv20_Kirby_row.bin", "hmtbtfw20.tlv";
		local-bd-address = [33 3f 12 7f 03 00];

		vddrfacmn-supply = <&vreg_pmu_rfa_cmn>;
		vddaon-supply = <&vreg_pmu_aon_0p59>;
		vddwlcx-supply = <&vreg_pmu_wlcx_0p8>;
		vddwlmx-supply = <&vreg_pmu_wlmx_0p85>;
		vddrfa0p8-supply = <&vreg_pmu_rfa_0p8>;
		vddrfa1p2-supply = <&vreg_pmu_rfa_1p2>;
		vddrfa1p8-supply = <&vreg_pmu_rfa_1p8>;

		max-speed = <3200000>;
	};
};

&q6apmbedai {
	clocks = <&q6prmcc LPASS_CLK_ID_SEC_TDM_IBIT LPASS_CLK_ATTRIBUTE_COUPLE_NO>,
		 <&q6prmcc LPASS_CLK_ID_SEC_TDM_EBIT LPASS_CLK_ATTRIBUTE_COUPLE_NO>,
		 <&q6prmcc LPASS_CLK_ID_SEC_MI2S_IBIT LPASS_CLK_ATTRIBUTE_COUPLE_NO>,
		 <&q6prmcc LPASS_CLK_ID_SEC_MI2S_EBIT LPASS_CLK_ATTRIBUTE_COUPLE_NO>,
		 <&q6prmcc LPASS_HW_MACRO_VOTE LPASS_CLK_ATTRIBUTE_COUPLE_NO>,
		 <&q6prmcc LPASS_HW_DCODEC_VOTE LPASS_CLK_ATTRIBUTE_COUPLE_NO>;
	clock-names = "sec-tdm-ibit",
		      "sec-tdm-ebit",
		      "sec-mi2s-ibit",
		      "sec-mi2s-ebit",
		      "lpass-macro",
		      "lpass-dcodec";
};

&uart15 {
	status = "okay";
};

&ufs_mem_hc {
	reset-gpios = <&tlmm 210 GPIO_ACTIVE_LOW>;

	vcc-supply = <&vreg_l17b_2p5>;
	vcc-max-microamp = <1300000>;
	vccq-supply = <&vreg_l1c_1p2>;
	vccq-max-microamp = <1200000>;

	status = "okay";
};

&ufs_mem_phy {
	vdda-phy-supply = <&vreg_l1d_0p88>;
	vdda-pll-supply = <&vreg_l3i_1p2>;

	status = "okay";
};

/*
 * DPAUX -> WCD9395 -> USB_SBU -> USB-C
 * eUSB2 DP/DM -> PM85550HS -> eUSB2 DP/DM -> WCD9395 -> USB-C
 * USB SS -> NB7VPQ904MMUTWG -> USB-C
 */

&usb_1 {
	dr_mode = "otg";
	usb-role-switch;
	role-switch-default-mode = "host";
	qcom,select-utmi-as-pipe-clk;
	qcom,host-ss-powerup-quirk;
	qcom,host-usb2-phy-reinit-quirk;

	status = "okay";
};

&usb_1_dwc3_hs {
	remote-endpoint = <&pmic_glink_hs_in>;
};

&usb_1_hsphy {
	vdd-supply = <&vreg_l1i_0p88>;
	vdda12-supply = <&vreg_l3i_1p2>;

	phys = <&eusb2_repeater>;

	status = "okay";
};

&usb_dp_qmpphy {
	vdda-phy-supply = <&vreg_l3i_1p2>;
	vdda-pll-supply = <&vreg_l3g_0p91>;

	status = "okay";
};

&usb_dp_qmpphy_out {
	remote-endpoint = <&redriver_ss_in>;
};

&xo_board {
	clock-frequency = <76800000>;
};

/* Camera sensor0 path: GC13A0 rear main on CCI0 and CSIPHY3. */
&camss {
	vdd-csiphy01-0p9-supply = <&vreg_l2i_0p88>;
	vdd-csiphy01-1p2-supply = <&vreg_l3i_1p2>;
	vdd-csiphy24-0p9-supply = <&vreg_l2i_0p88>;
	vdd-csiphy24-1p2-supply = <&vreg_l3i_1p2>;
	vdd-csiphy35-0p9-supply = <&vreg_l2i_0p88>;
	vdd-csiphy35-1p2-supply = <&vreg_l3i_1p2>;
	status = "okay";

	ports {
		port@1 {
			reg = <1>;

			csiphy1_ep: endpoint {
				data-lanes = <0>;
				remote-endpoint = <&sc202cs_ep>;
			};
		};

		port@3 {
			reg = <3>;

			csiphy3_ep: endpoint {
				data-lanes = <0 1 2 3>;
				remote-endpoint = <&gc13a0_ep>;
			};
		};

		port@5 {
			reg = <5>;

			csiphy5_ep: endpoint {
				data-lanes = <0 1 2 3>;
				remote-endpoint = <&sc820cs_ep>;
			};
		};
	};
};

&cci0 {
	assigned-clocks = <&camcc CAM_CC_CAMNOC_AXI_NRT_CLK>,
			  <&camcc CAM_CC_CPAS_AHB_CLK>,
			  <&camcc CAM_CC_CCI_0_CLK_SRC>;
	assigned-clock-rates = <300000000>, <80000000>, <37500000>;

	status = "okay";
};

&cci0_i2c0 {
	camera@11 {
		compatible = "galaxycore,gc13a0";
		reg = <0x11>;

		pinctrl-0 = <&cam0_default>, <&cam0_reset_default>;
		pinctrl-names = "default";
		reset-gpios = <&tlmm 11 GPIO_ACTIVE_LOW>;

		clocks = <&camcc CAM_CC_MCLK0_CLK>;
		assigned-clocks = <&camcc CAM_CC_MCLK0_CLK>;
		assigned-clock-rates = <19200000>;

		avdd-supply = <&cam_ldo4_2p8>;
		dovdd-supply = <&cam_ldo3_1p8>;
		dvdd-supply = <&cam_ldo1_1p2>;
		lens-focus = <&gc13a0_vcm>;
		flash-leds = <&pm8550_flash_yellow &pm8550_flash_white>;

		orientation = <1>;
		rotation = <90>;

		port {
			gc13a0_ep: endpoint {
				data-lanes = <0 1 2 3>;
				link-frequencies = /bits/ 64 <560000000>;
				remote-endpoint = <&csiphy3_ep>;
			};
		};
	};

	/*
	 * Android actuator packet power sequence uses vendor camera LDO
	 * seq_type 17, which maps to ET5907 LDO5 at 2.784 V. Using the
	 * PMIC cam_vaf rail leaves GT9772B unpowered and causes I2C NACK.
	 */
	gc13a0_vcm: camera-lens@c {
		compatible = "giantec,gt9772b";
		reg = <0x0c>;
		vin-supply = <&cam_ldo5_2p78>;
		vdd-supply = <&cam_ldo5_2p78>;
	};
};

&cci0_i2c1 {
	camera@36 {
		compatible = "smartsens,sc202cs";
		reg = <0x36>;

		pinctrl-0 = <&cam1_default>, <&cam2_reset_default>;
		pinctrl-names = "default";
		reset-gpios = <&tlmm 15 GPIO_ACTIVE_LOW>;

		clocks = <&camcc CAM_CC_MCLK1_CLK>;
		assigned-clocks = <&camcc CAM_CC_MCLK1_CLK>;
		assigned-clock-rates = <19200000>;

		ldo7-supply = <&cam_ldo7_2p024>;
		ldo6-supply = <&cam_ldo6_2p78>;

		orientation = <1>;
		rotation = <90>;

		port {
			sc202cs_ep: endpoint {
				data-lanes = <0>;
				link-frequencies = /bits/ 64 <560000000>;
				remote-endpoint = <&csiphy1_ep>;
			};
		};
	};
};

&cci1 {
	assigned-clocks = <&camcc CAM_CC_CAMNOC_AXI_NRT_CLK>,
			  <&camcc CAM_CC_CPAS_AHB_CLK>,
			  <&camcc CAM_CC_CCI_1_CLK_SRC>;
	assigned-clock-rates = <300000000>, <80000000>, <37500000>;
	pinctrl-0 = <&cci1_0_default>;
	pinctrl-1 = <&cci1_0_sleep>;

	status = "okay";
};

&cci1_i2c0 {
	clock-frequency = <100000>;

	camera@36 {
		compatible = "smartsens,sc820cs";
		reg = <0x36>;

		pinctrl-0 = <&cam3_default>, <&cam1_reset_default>;
		pinctrl-names = "default";
		reset-gpios = <&tlmm 109 GPIO_ACTIVE_LOW>;

		clocks = <&camcc CAM_CC_MCLK3_CLK>;
		assigned-clocks = <&camcc CAM_CC_MCLK3_CLK>;
		assigned-clock-rates = <19200000>;

		ldo7-supply = <&cam_ldo7_2p024>;
		ldo2-supply = <&cam_ldo2_1p31>;
		ldo3-supply = <&cam_ldo3_1p8>;

		orientation = <0>;
		rotation = <270>;

		port {
			sc820cs_ep: endpoint {
				data-lanes = <0 1 2 3>;
				link-frequencies = /bits/ 64 <364800000>;
				remote-endpoint = <&csiphy5_ep>;
			};
		};
	};

	camera_pmic: regulator@35 {
		compatible = "vendor,et5907", "willsemi,wl2868c";
		reg = <0x35>;

		pinctrl-0 = <&camera_pmic_en_default>;
		pinctrl-names = "default";
		enable-gpios = <&tlmm 126 GPIO_ACTIVE_HIGH>;

		vin1-supply = <&vreg_s6c_1p8>;
		vin2-supply = <&vreg_bob1>;
		vin3-supply = <&vreg_l10b_1p8>;

		regulators {
			cam_ldo1_1p2: ldo1 {
				regulator-name = "cam_ldo1_1p2";
				regulator-min-microvolt = <1200000>;
				regulator-max-microvolt = <1200000>;
			};

			cam_ldo2_1p31: ldo2 {
				regulator-name = "cam_ldo2_1p31";
				regulator-min-microvolt = <1312000>;
				regulator-max-microvolt = <1312000>;
			};

			cam_ldo3_1p8: ldo3 {
				regulator-name = "cam_ldo3_1p8";
				regulator-min-microvolt = <1800000>;
				regulator-max-microvolt = <2784000>;
			};

			cam_ldo4_2p8: ldo4 {
				regulator-name = "cam_ldo4_2p8";
				regulator-min-microvolt = <2800000>;
				regulator-max-microvolt = <2800000>;
			};


			cam_ldo5_2p78: ldo5 {
				regulator-name = "cam_ldo5_2p78";
				regulator-min-microvolt = <2784000>;
				regulator-max-microvolt = <2784000>;
				regulator-enable-ramp-delay = <10000>;
			};
			cam_ldo6_2p78: ldo6 {
				regulator-name = "cam_ldo6_2p78";
				regulator-min-microvolt = <2784000>;
				regulator-max-microvolt = <2784000>;
			};

			cam_ldo7_2p024: ldo7 {
				regulator-name = "cam_ldo7_2p024";
				regulator-min-microvolt = <2024000>;
				regulator-max-microvolt = <2024000>;
			};
		};
	};
};
/* Keep UART14 enabled for WCN7850 Bluetooth bring-up. */

/*
 * SteamOS ARM Port changes on top of the GUF296 tree, from the TB321FU
 * port notes:
 *  - the microphones need MIC BIAS4 on AMIC4 and SoundWire port 1 for capture
 *    (fixed above)
 *  - held in landscape, 0x5a is the left motor and 0x5b the right one
 *    (labels fixed above)
 *  - the video decoder only takes the tablet's own signed vpu33_p4 image
 *  - the Wi-Fi wake line on PCIe 0 is active low
 *  - the codec and Wi-Fi keep three rails on through s2idle: let them drop
 *    to low power there
 */
&iris {
	firmware-name = "qcom/sm8650/lenovo/tb321fu/vpu33_p4.mbn";
};

&pcie0 {
	wake-gpios = <&tlmm 96 GPIO_ACTIVE_LOW>;
};

&vreg_l15b_1p8 {
	regulator-state-mem {
		regulator-on-in-suspend;
		regulator-mode = <RPMH_REGULATOR_MODE_LPM>;
	};
};

&vreg_bob1 {
	regulator-state-mem {
		regulator-on-in-suspend;
		regulator-mode = <RPMH_REGULATOR_MODE_LPM>;
	};
};

&vreg_l3c_1p2 {
	regulator-state-mem {
		regulator-on-in-suspend;
		regulator-mode = <RPMH_REGULATOR_MODE_LPM>;
	};
};

/*
 * No camera support yet (the sensor drivers are left out): with the camera
 * subsystem up but nothing behind it, its video nodes fail and WirePlumber's
 * v4l2 monitor stalls on them, so no audio stream ever links.
 */
&camss {
	status = "disabled";
};

&cci0 {
	status = "disabled";
};

&cci1 {
	status = "disabled";
};
